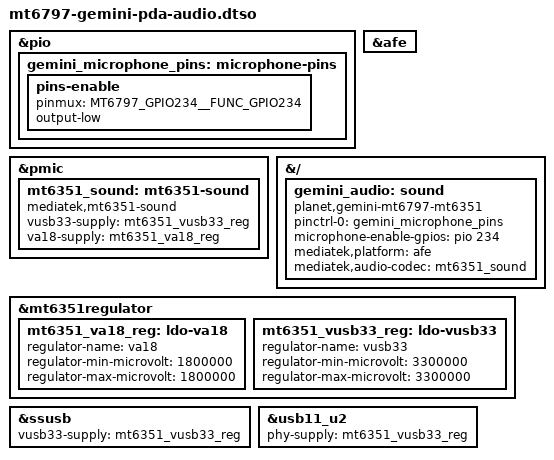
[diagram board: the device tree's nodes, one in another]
// SPDX-License-Identifier: GPL-2.0-only
/*
 * Planet Computers Gemini PDA MT6797/MT6351 audio overlay.
 *
 * This overlay is deliberately not part of mt6797-gemini-pda.dtb.  It enables
 * the MT6797 AFE, MT6351 codec and the Gemini machine-card capture gate.
 * The external speaker amplifiers and headset contact selection still need
 * separate routing support.
 *
 * Evidence:
 * - The Gemini base DT identifies the parent PMIC as MT6351:
 *   arch/arm64/boot/dts/mediatek/mt6797.dtsi:380-421.
 * - The MT6351 binding requires its sound node to be a child of the PMIC
 *   wrapper: Documentation/devicetree/bindings/sound/mt6351.txt:3-16.
 * - The MT6797 machine binding pairs the AFE and codec phandles exactly as
 *   below: Documentation/devicetree/bindings/sound/mt6797-mt6351.txt:3-14.
 * - gemian/gemini-linux-kernel-3.18 aeon6797_6m_n.dts assigns headphone_en
 *   to GPIO234. mt_soc_audio_6797/mt_soc_codec_63xx.c calls that enable in
 *   TurnOnADcPowerDCC(), before starting either capture preamplifier, and
 *   lowers it on teardown. AudDrv_Gpio.c uses active-high polarity.
 * - The hpdepop states on GPIO243/244 are used by EXTAMP/EXTAMP2 in that
 *   vendor tree, not by its disabled HPDEPOP_Select implementation. They
 *   must not be treated as a headphone-enable signal.
 */

/dts-v1/;
/plugin/;

#include <dt-bindings/gpio/gpio.h>
#include <dt-bindings/pinctrl/mt6797-pinfunc.h>

&pio {
	gemini_microphone_pins: microphone-pins {
		pins-enable {
			pinmux = <MT6797_GPIO234__FUNC_GPIO234>;
			output-low;
		};
	};
};

&afe {
	status = "okay";
};

&pmic {
	mt6351_sound: mt6351-sound {
		compatible = "mediatek,mt6351-sound";
		vusb33-supply = <&mt6351_vusb33_reg>;
		va18-supply = <&mt6351_va18_reg>;
		status = "okay";
	};
};

&{/} {
	gemini_audio: sound {
		compatible = "planet,gemini-mt6797-mt6351";
		pinctrl-names = "default";
		pinctrl-0 = <&gemini_microphone_pins>;
		microphone-enable-gpios = <&pio 234 GPIO_ACTIVE_HIGH>;
		mediatek,platform = <&afe>;
		mediatek,audio-codec = <&mt6351_sound>;
		status = "okay";
	};
};

/* Audio must share these rails with both USB ports through real consumers. */
&mt6351regulator {
	mt6351_va18_reg: ldo-va18 {
		regulator-name = "va18";
		regulator-min-microvolt = <1800000>;
		regulator-max-microvolt = <1800000>;
	};

	mt6351_vusb33_reg: ldo-vusb33 {
		regulator-name = "vusb33";
		regulator-min-microvolt = <3300000>;
		regulator-max-microvolt = <3300000>;
	};

};

&ssusb {
	vusb33-supply = <&mt6351_vusb33_reg>;
};

&usb11_u2 {
	phy-supply = <&mt6351_vusb33_reg>;
};
